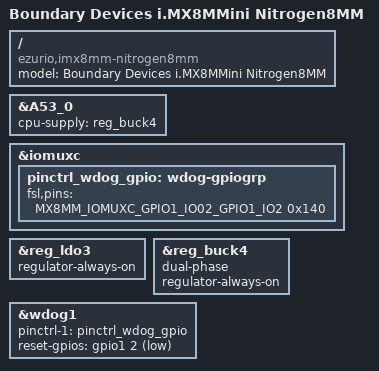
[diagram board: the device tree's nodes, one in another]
// SPDX-License-Identifier: (GPL-2.0+ OR MIT)
/*
 * Copyright 2018 Boundary Devices
 */
#include "imx8mm-nitrogen8mm_rev2.dts"

/ {
	model = "Boundary Devices i.MX8MMini Nitrogen8MM";
	compatible = "ezurio,imx8mm-nitrogen8mm", "fsl,imx8mm";
};

&A53_0 {
	cpu-supply = <&reg_buck4>;
};

&iomuxc {
	pinctrl_wdog_gpio: wdog-gpiogrp {
		fsl,pins = <
			MX8MM_IOMUXC_GPIO1_IO02_GPIO1_IO2	0x140
		>;
	};
};

&reg_ldo3 {
	regulator-always-on;
};

&reg_buck4 {
	dual-phase;
	regulator-always-on;
};

&wdog1 {
	pinctrl-names = "default", "gpio";
	pinctrl-1 = <&pinctrl_wdog_gpio>;
	reset-gpios = <&gpio1 2 GPIO_ACTIVE_LOW>;
};
